AUTOSAR XML (schema 4-2-2)
package /Components
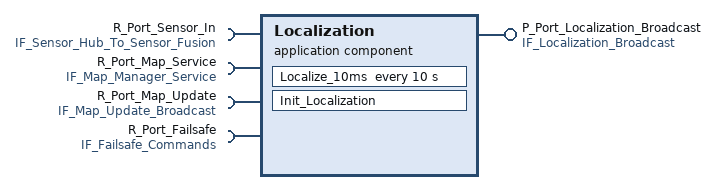
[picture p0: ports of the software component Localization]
  application sw component type Localization
    provide port P_Port_Localization_Broadcast: provided-interface=IF_Localization_Broadcast
    4 x require port:
      R_Port_Sensor_In: required-interface=IF_Sensor_Hub_To_Sensor_Fusion
      R_Port_Map_Service: required-interface=IF_Map_Manager_Service
      R_Port_Map_Update: required-interface=IF_Map_Update_Broadcast
      R_Port_Failsafe: required-interface=IF_Failsafe_Commands
    behavior Localization_InternalBehavior
      init event Localization_Init: start-on-event=Init_Localization
      timing event Localization_10ms: start-on-event=Localize_10ms, period=10
      runnable Init_Localization
        parameter access InitParamAccess_Localization_Config: accessed-parameter=R_Port_Sensor_In.IMU_Data
      runnable Localize_10ms: minimum-start-interval=10
        data-receive-point-by-arguments:
          access Read_IMU_Data: accessed-variable=R_Port_Sensor_In.IMU_Data
          access Read_GNSS_Fix: accessed-variable=R_Port_Sensor_In.GNSS_Fix
          access Read_Map_Version: accessed-variable=R_Port_Map_Update.Map_Version
        data-send-points:
          access Send_Ego_Pose: accessed-variable=P_Port_Localization_Broadcast.Ego_Pose
          access Send_Ego_Velocity: accessed-variable=P_Port_Localization_Broadcast.Ego_Velocity
          access Send_Localization_Status: accessed-variable=P_Port_Localization_Broadcast.Localization_Status
        sync call Call_GetHDMapTile: operation=R_Port_Map_Service.GetHDMapTile, timeout=30
